VERSION ""

NS_ :

BS_:

BU_:

BO_ 3221225472 VECTOR__INDEPENDENT_SIG_MSG: 0 Vector__XXX
 SG_ StateOfChargeBMS : 0|8@0+ (0.5,3) [0|100] "%" Vector__XXX
 SG_ response : 0|16@0+ (1,0) [0|0] "unit" Vector__XXX
 SG_ service : 0|8@0+ (1,0) [0|0] "" Vector__XXX
 SG_ MinCellVoltage : 0|8@0+ (0.02,0) [2.8|4.2] "V" Vector__XXX
 SG_ MaxCellVoltage : 0|8@0+ (0.02,0) [2.8|4.2] "V" Vector__XXX
 SG_ StateOfChargeDisplay : 0|8@0+ (0.5,3) [0|0] "%" Vector__XXX
 SG_ BatteryTemperature1 : 0|8@0- (1,0) [0|0] "degC" Vector__XXX
 SG_ BatteryTemperature2 : 0|8@0- (1,0) [0|0] "degC" Vector__XXX
 SG_ BatteryTemperature3 : 0|8@0- (1,0) [0|0] "degC" Vector__XXX
 SG_ BatteryTemperature4 : 0|8@0- (1,0) [0|0] "degC" Vector__XXX
 SG_ BatteryMinTemperature : 0|8@0- (1,0) [0|0] "degC" Vector__XXX
 SG_ BatteryMaxTemperature : 0|8@0- (1,0) [0|0] "degC" Vector__XXX
 SG_ BatteryHeaterTemperature1 : 0|8@0- (1,0) [0|0] "degC" Vector__XXX
 SG_ BatteryVoltageAuxillary : 0|8@0+ (0.1,0) [11|14.6] "V" Vector__XXX
 SG_ BatteryTemperature5 : 0|8@0- (1,0) [0|0.5] "V" Vector__XXX
 SG_ BatteryFanFeedback : 0|8@0+ (1,0) [0|120] "Hz" Vector__XXX
 SG_ BatteryFanStatus : 0|8@0+ (1,0) [0|9] "" Vector__XXX
 SG_ NormalChargePort : 0|1@0+ (1,0) [0|0] "" Vector__XXX
 SG_ RapidChargePort : 0|1@0+ (1,0) [0|0] "" Vector__XXX
 SG_ OperatingTime : 0|32@0+ (0.00027777777,0) [0|1000000] "hours" Vector__XXX
 SG_ MinDeterioration : 0|16@0+ (0.1,0) [0|100] "%" Vector__XXX
 SG_ MinDeteriorationCellNo : 0|8@0+ (1,0) [0|98] "" Vector__XXX
 SG_ MinCellVoltageCellNo : 0|8@0+ (1,0) [0|0] "" Vector__XXX
 SG_ MaxCellVoltageCellNo : 0|8@0+ (1,0) [0|0] "" Vector__XXX
 SG_ Charging : 0|1@0+ (1,0) [0|0] "" Vector__XXX
 SG_ CCC_CumulativeChargeCurrent : 0|32@0+ (0.1,0) [0|1000000] "Ah" Vector__XXX
 SG_ CDC_CumulativeDischargeCurrent : 0|32@0+ (0.1,0) [0|1000000] "Ah" Vector__XXX
 SG_ CEC_CumulativeEnergyCharged : 0|32@0+ (0.1,0) [0|1000000] "kWh" Vector__XXX
 SG_ CED_CumulativeEnergyDischarged : 0|32@0+ (0.1,0) [0|1000000] "kWh" Vector__XXX
 SG_ BMSMainRelay : 0|1@0+ (1,0) [0|0] "" Vector__XXX
 SG_ BMSIgnition : 0|1@0+ (1,0) [0|0] "" Vector__XXX
 SG_ BatteryDCVoltage : 0|16@0+ (0.1,0) [0|0] "V" Vector__XXX
 SG_ BatteryCurrent : 0|16@0- (0.1,0) [-230|230] "A" Vector__XXX
 SG_ BatteryAvailableChargePower : 0|16@0+ (0.01,0) [0|270] "kW" Vector__XXX
 SG_ BatteryAvailableDischargePower : 0|16@0+ (0.01,0) [0|270] "kW" Vector__XXX
 SG_ CellVoltage01 : 0|8@0+ (0.02,0) [2.8|4.2] "V" Vector__XXX
 SG_ CellVoltage02 : 0|8@0+ (0.02,0) [2.8|4.2] "V" Vector__XXX
 SG_ CellVoltage03 : 0|8@0+ (0.02,0) [2.8|4.2] "V" Vector__XXX
 SG_ CellVoltage04 : 0|8@0+ (0.02,0) [2.8|4.2] "V" Vector__XXX
 SG_ CellVoltage05 : 0|8@0+ (0.02,0) [2.8|4.2] "V" Vector__XXX
 SG_ CellVoltage06 : 0|8@0+ (0.02,0) [2.8|4.2] "V" Vector__XXX
 SG_ CellVoltage07 : 0|8@0+ (0.02,0) [2.8|4.2] "V" Vector__XXX
 SG_ CellVoltage08 : 0|8@0+ (0.02,0) [2.8|4.2] "V" Vector__XXX
 SG_ CellVoltage09 : 0|8@0+ (0.02,0) [2.8|4.2] "V" Vector__XXX
 SG_ CellVoltage10 : 0|8@0+ (0.02,0) [2.8|4.2] "V" Vector__XXX
 SG_ CellVoltage11 : 0|8@0+ (0.02,0) [2.8|4.2] "V" Vector__XXX
 SG_ CellVoltage12 : 0|8@0+ (0.02,0) [2.8|4.2] "V" Vector__XXX
 SG_ CellVoltage13 : 0|8@0+ (0.02,0) [2.8|4.2] "V" Vector__XXX
 SG_ CellVoltage14 : 0|8@0+ (0.02,0) [2.8|4.2] "V" Vector__XXX
 SG_ CellVoltage15 : 0|8@0+ (0.02,0) [2.8|4.2] "V" Vector__XXX
 SG_ CellVoltage16 : 0|8@0+ (0.02,0) [2.8|4.2] "V" Vector__XXX
 SG_ CellVoltage17 : 0|8@0+ (0.02,0) [2.8|4.2] "V" Vector__XXX
 SG_ CellVoltage18 : 0|8@0+ (0.02,0) [2.8|4.2] "V" Vector__XXX
 SG_ CellVoltage19 : 0|8@0+ (0.02,0) [2.8|4.2] "V" Vector__XXX
 SG_ CellVoltage20 : 0|8@0+ (0.02,0) [2.8|4.2] "V" Vector__XXX
 SG_ StateOfHealth : 0|16@0+ (0.1,0) [0|100] "%" Vector__XXX
 SG_ IndoorTemperature : 0|8@0+ (0.5,-40) [-50|50] "degC" Vector__XXX
 SG_ response : 0|16@0+ (1,0) [0|0] "unit" Vector__XXX
 SG_ service : 0|8@0+ (1,0) [0|0] "" Vector__XXX
 SG_ OutdoorTemperature : 0|8@0+ (0.5,-40) [-50|50] "degC" Vector__XXX
 SG_ VehicleSpeed : 0|8@0+ (1,0) [0|200] "kmh" Vector__XXX
 SG_ response : 0|16@0+ (1,0) [0|0] "" Vector__XXX
 SG_ service : 0|8@0+ (1,0) [0|0] "" Vector__XXX
 SG_ TirePressureFrontLeft : 0|8@0+ (0.2,0) [0|120] "psi" Vector__XXX
 SG_ TirePressureFrontRight : 0|8@0+ (0.2,0) [0|120] "psi" Vector__XXX
 SG_ TirePressureBackLeft : 0|8@0+ (0.2,0) [0|120] "psi" Vector__XXX
 SG_ TirePressureBackRight : 0|8@0+ (0.2,0) [0|120] "psi" Vector__XXX
 SG_ TireTemperatureFrontLeft : 0|8@0+ (1,-50) [-40|65] "degC" Vector__XXX
 SG_ TireTemperatureFrontRight : 0|8@0+ (1,-50) [-40|65] "degC" Vector__XXX
 SG_ TireTemperatureBackLeft : 0|8@0+ (1,-50) [-40|65] "degC" Vector__XXX
 SG_ TireTemperatureBackRight : 0|8@0+ (1,-50) [-40|65] "degC" Vector__XXX

BO_ 3 gnss_pos: 8 Vector__XXX
 SG_ PositionAccuracy : 58|6@1+ (1,0) [0|63] "m" Vector__XXX
 SG_ Latitude : 1|28@1+ (1E-006,-90) [-90|90] "deg" Vector__XXX
 SG_ Longitude : 29|29@1+ (1E-006,-180) [-180|180] "deg" Vector__XXX
 SG_ PositionValid : 0|1@1+ (1,0) [0|1] "" Vector__XXX

BO_ 2 gnss_time: 6 Vector__XXX
 SG_ TimeValid : 0|1@1+ (1,0) [0|1] "" Vector__XXX
 SG_ TimeConfirmed : 1|1@1+ (1,0) [0|1] "" Vector__XXX
 SG_ Epoch : 8|40@1+ (0.001,1577840400) [1577840400|2677352027] "sec" Vector__XXX

BO_ 5 gnss_attitude: 8 Vector__XXX
 SG_ AttitudeValid : 0|1@1+ (1,0) [0|1] "" Vector__XXX
 SG_ Roll : 1|12@1+ (0.1,-180) [-180|180] "deg" Vector__XXX
 SG_ Pitch : 22|12@1+ (0.1,-90) [-90|90] "deg" Vector__XXX
 SG_ Heading : 43|12@1+ (0.1,0) [0|360] "deg" Vector__XXX
 SG_ RollAccuracy : 13|9@1+ (0.1,0) [0|50] "deg" Vector__XXX
 SG_ PitchAccuracy : 34|9@1+ (0.1,0) [0|50] "deg" Vector__XXX
 SG_ HeadingAccuracy : 55|9@1+ (0.1,0) [0|50] "deg" Vector__XXX

BO_ 6 gnss_odo: 8 Vector__XXX
 SG_ DistanceTrip : 1|22@1+ (1,0) [0|4194303] "m" Vector__XXX
 SG_ DistanceAccuracy : 23|19@1+ (1,0) [0|524287] "m" Vector__XXX
 SG_ DistanceValid : 0|1@1+ (1,0) [0|1] "" Vector__XXX
 SG_ DistanceTotal : 42|22@1+ (1,0) [0|4194303] "km" Vector__XXX

BO_ 1 gnss_status: 1 Vector__XXX
 SG_ FixType : 0|3@1+ (1,0) [0|5] "" Vector__XXX
 SG_ Satellites : 3|5@1+ (1,0) [0|31] "" Vector__XXX

BO_ 4 gnss_altitude: 4 Vector__XXX
 SG_ AltitudeValid : 0|1@1+ (1,0) [0|1] "" Vector__XXX
 SG_ Altitude : 1|18@1+ (0.1,-6000) [-6000|20000] "m" Vector__XXX
 SG_ AltitudeAccuracy : 19|13@1+ (1,0) [0|8000] "m" Vector__XXX

BO_ 8 gnss_geofence: 2 Vector__XXX
 SG_ FenceValid : 0|1@1+ (1,0) [0|1] "" Vector__XXX
 SG_ FenceCombined : 1|2@1+ (1,0) [0|1] "" Vector__XXX
 SG_ Fence1 : 8|2@1+ (1,0) [0|1] "" Vector__XXX
 SG_ Fence2 : 10|2@1+ (1,0) [0|1] "" Vector__XXX
 SG_ Fence3 : 12|2@1+ (1,0) [0|1] "" Vector__XXX
 SG_ Fence4 : 14|2@1+ (1,0) [0|1] "" Vector__XXX

BO_ 7 gnss_speed: 5 Vector__XXX
 SG_ Speed : 1|20@1+ (0.001,0) [0|1048.575] "m/s" Vector__XXX
 SG_ SpeedAccuracy : 21|19@1+ (0.001,0) [0|524.287] "m/s" Vector__XXX
 SG_ SpeedValid : 0|1@1+ (1,0) [0|1] "" Vector__XXX

BO_ 9 gnss_imu: 8 Vector__XXX
 SG_ AccelerationX : 1|10@1+ (0.125,-64) [-64|63.875] "m/s^2" Vector__XXX
 SG_ AccelerationY : 11|10@1+ (0.125,-64) [-64|63.875] "m/s^2" Vector__XXX
 SG_ AccelerationZ : 21|10@1+ (0.125,-64) [-64|63.875] "m/s^2" Vector__XXX
 SG_ AngularRateX : 31|11@1+ (0.25,-256) [-256|255.75] "deg/s" Vector__XXX
 SG_ AngularRateY : 42|11@1+ (0.25,-256) [-256|255.75] "deg/s" Vector__XXX
 SG_ AngularRateZ : 53|11@1+ (0.25,-256) [-256|255.75] "deg/s" Vector__XXX
 SG_ ImuValid : 0|1@1+ (1,0) [0|1] "" Vector__XXX

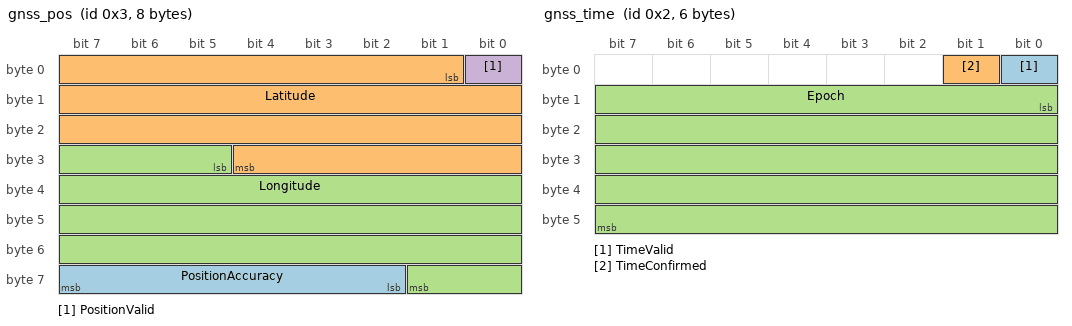
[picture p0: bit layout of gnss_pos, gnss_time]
BO_ 19 gnss_pos: 8 Vector__XXX
 SG_ PositionAccuracy : 58|6@1+ (1,0) [0|63] "m" Vector__XXX
 SG_ Latitude : 1|28@1+ (1E-006,-90) [-90|90] "deg" Vector__XXX
 SG_ Longitude : 29|29@1+ (1E-006,-180) [-180|180] "deg" Vector__XXX
 SG_ PositionValid : 0|1@1+ (1,0) [0|1] "" Vector__XXX

BO_ 18 gnss_time: 6 Vector__XXX
 SG_ TimeValid : 0|1@1+ (1,0) [0|1] "" Vector__XXX
 SG_ TimeConfirmed : 1|1@1+ (1,0) [0|1] "" Vector__XXX
 SG_ Epoch : 8|40@1+ (0.001,1577840400) [1577840400|2677352027] "sec" Vector__XXX

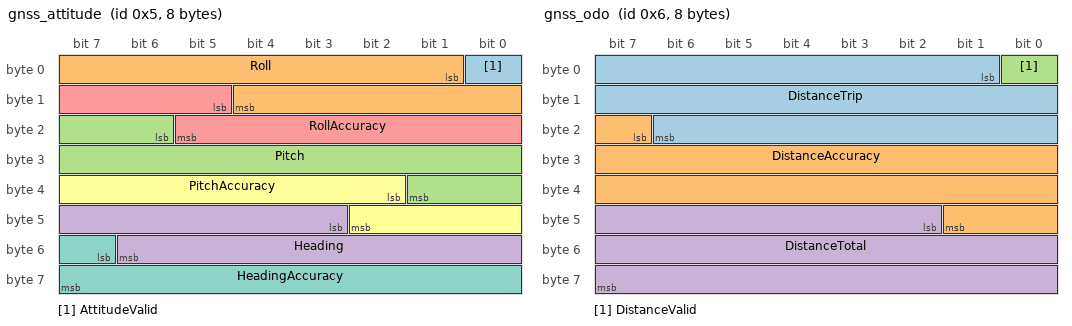
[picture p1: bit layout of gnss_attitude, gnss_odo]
BO_ 21 gnss_attitude: 8 Vector__XXX
 SG_ AttitudeValid : 0|1@1+ (1,0) [0|1] "" Vector__XXX
 SG_ Roll : 1|12@1+ (0.1,-180) [-180|180] "deg" Vector__XXX
 SG_ Pitch : 22|12@1+ (0.1,-90) [-90|90] "deg" Vector__XXX
 SG_ Heading : 43|12@1+ (0.1,0) [0|360] "deg" Vector__XXX
 SG_ RollAccuracy : 13|9@1+ (0.1,0) [0|50] "deg" Vector__XXX
 SG_ PitchAccuracy : 34|9@1+ (0.1,0) [0|50] "deg" Vector__XXX
 SG_ HeadingAccuracy : 55|9@1+ (0.1,0) [0|50] "deg" Vector__XXX

BO_ 22 gnss_odo: 8 Vector__XXX
 SG_ DistanceTrip : 1|22@1+ (1,0) [0|4194303] "m" Vector__XXX
 SG_ DistanceAccuracy : 23|19@1+ (1,0) [0|524287] "m" Vector__XXX
 SG_ DistanceValid : 0|1@1+ (1,0) [0|1] "" Vector__XXX
 SG_ DistanceTotal : 42|22@1+ (1,0) [0|4194303] "km" Vector__XXX

BO_ 17 gnss_status: 1 Vector__XXX
 SG_ FixType : 0|3@1+ (1,0) [0|5] "" Vector__XXX
 SG_ Satellites : 3|5@1+ (1,0) [0|31] "" Vector__XXX

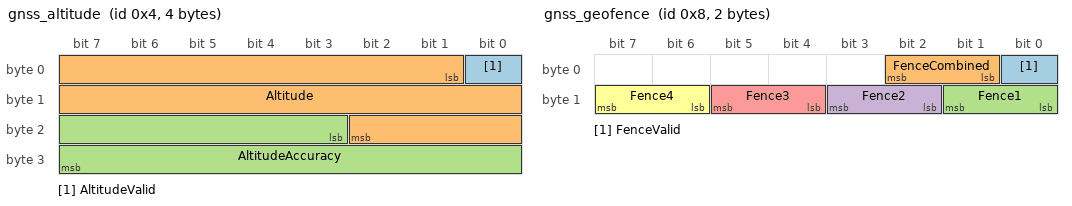
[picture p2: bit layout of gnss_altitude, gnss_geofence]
BO_ 20 gnss_altitude: 4 Vector__XXX
 SG_ AltitudeValid : 0|1@1+ (1,0) [0|1] "" Vector__XXX
 SG_ Altitude : 1|18@1+ (0.1,-6000) [-6000|20000] "m" Vector__XXX
 SG_ AltitudeAccuracy : 19|13@1+ (1,0) [0|8000] "m" Vector__XXX

BO_ 24 gnss_geofence: 2 Vector__XXX
 SG_ FenceValid : 0|1@1+ (1,0) [0|1] "" Vector__XXX
 SG_ FenceCombined : 1|2@1+ (1,0) [0|1] "" Vector__XXX
 SG_ Fence1 : 8|2@1+ (1,0) [0|1] "" Vector__XXX
 SG_ Fence2 : 10|2@1+ (1,0) [0|1] "" Vector__XXX
 SG_ Fence3 : 12|2@1+ (1,0) [0|1] "" Vector__XXX
 SG_ Fence4 : 14|2@1+ (1,0) [0|1] "" Vector__XXX

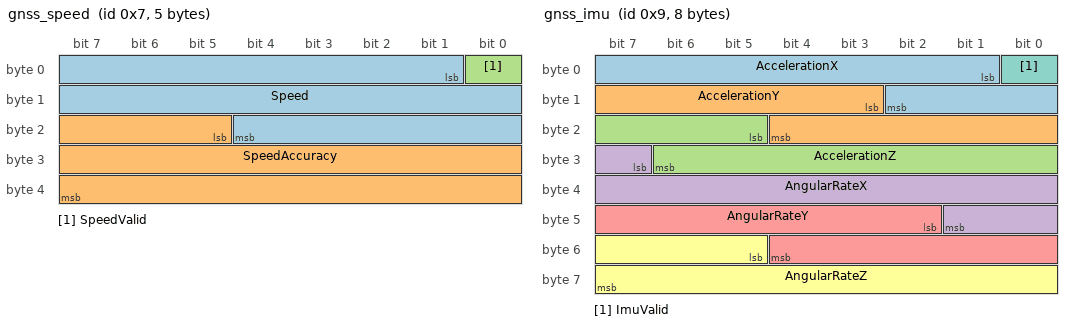
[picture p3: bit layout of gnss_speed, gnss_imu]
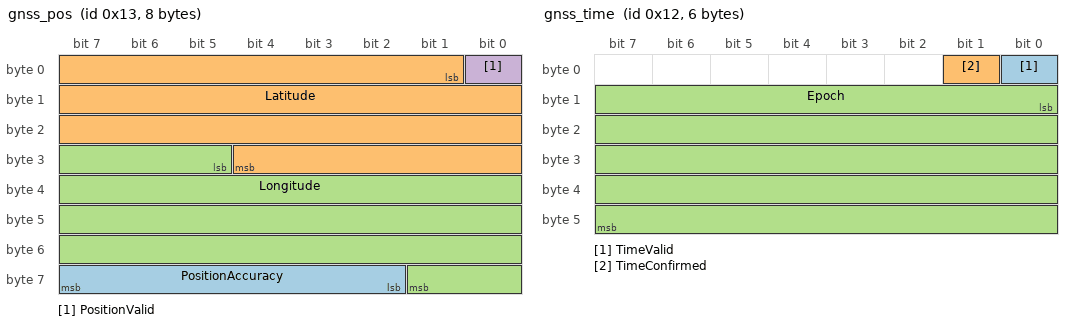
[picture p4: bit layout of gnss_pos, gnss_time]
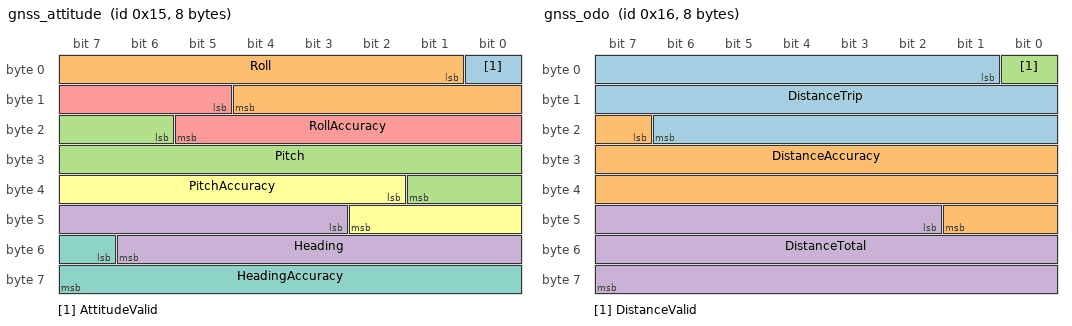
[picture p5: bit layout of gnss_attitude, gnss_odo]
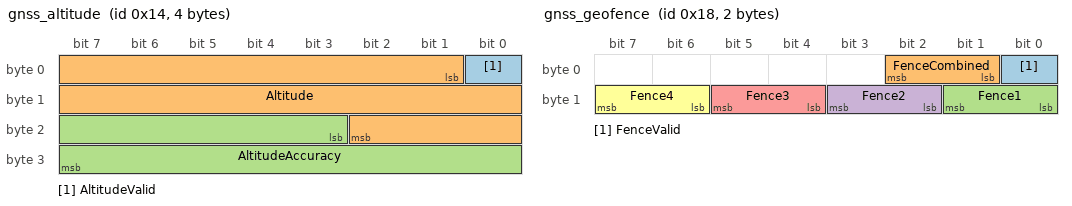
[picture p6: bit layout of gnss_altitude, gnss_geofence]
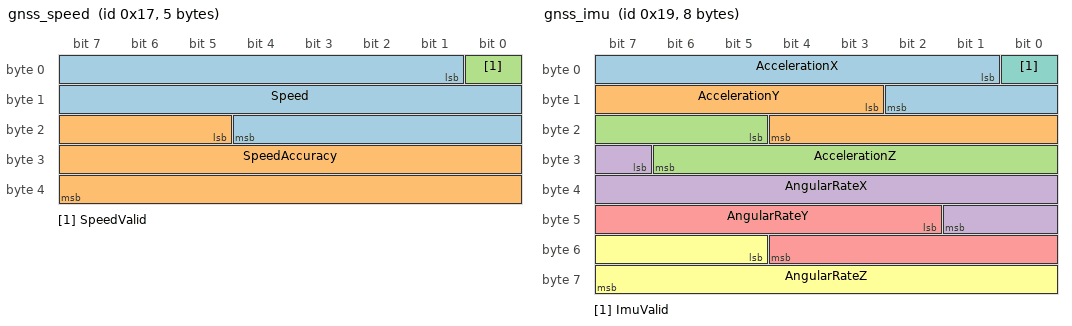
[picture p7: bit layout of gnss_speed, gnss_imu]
BO_ 23 gnss_speed: 5 Vector__XXX
 SG_ Speed : 1|20@1+ (0.001,0) [0|1048.575] "m/s" Vector__XXX
 SG_ SpeedAccuracy : 21|19@1+ (0.001,0) [0|524.287] "m/s" Vector__XXX
 SG_ SpeedValid : 0|1@1+ (1,0) [0|1] "" Vector__XXX

BO_ 25 gnss_imu: 8 Vector__XXX
 SG_ AccelerationX : 1|10@1+ (0.125,-64) [-64|63.875] "m/s^2" Vector__XXX
 SG_ AccelerationY : 11|10@1+ (0.125,-64) [-64|63.875] "m/s^2" Vector__XXX
 SG_ AccelerationZ : 21|10@1+ (0.125,-64) [-64|63.875] "m/s^2" Vector__XXX
 SG_ AngularRateX : 31|11@1+ (0.25,-256) [-256|255.75] "deg/s" Vector__XXX
 SG_ AngularRateY : 42|11@1+ (0.25,-256) [-256|255.75] "deg/s" Vector__XXX
 SG_ AngularRateZ : 53|11@1+ (0.25,-256) [-256|255.75] "deg/s" Vector__XXX
 SG_ ImuValid : 0|1@1+ (1,0) [0|1] "" Vector__XXX

CM_ BO_ 3221225472 "This is a message for not used signals, created by Vector CANdb++ DBC OLE DB Provider.";
CM_ BO_ 3 "GNSS position";
CM_ SG_ 3 PositionAccuracy "Accuracy of position";
CM_ SG_ 3 Latitude "Latitude";
CM_ SG_ 3 Longitude "Longitude";
CM_ SG_ 3 PositionValid "Position validity";
CM_ BO_ 2 "GNSS time";
CM_ SG_ 2 TimeValid "Time validity";
CM_ SG_ 2 TimeConfirmed "Time confirmed";
CM_ SG_ 2 Epoch "Epoch time";
CM_ BO_ 5 "GNSS attitude";
CM_ SG_ 5 AttitudeValid "Attitude validity";
CM_ SG_ 5 Roll "Vehicle roll";
CM_ SG_ 5 Pitch "Vehicle pitch";
CM_ SG_ 5 Heading "Vehicle heading";
CM_ SG_ 5 RollAccuracy "Vehicle roll accuracy";
CM_ SG_ 5 PitchAccuracy "Vehicle pitch accuracy";
CM_ SG_ 5 HeadingAccuracy "Vehicle heading accuracy";
CM_ BO_ 6 "GNSS odometer";
CM_ SG_ 6 DistanceTrip "Distance traveled since last reset";
CM_ SG_ 6 DistanceAccuracy "Distance accuracy (1-sigma)";
CM_ SG_ 6 DistanceTotal "Distance traveled in total";
CM_ BO_ 1 "GNSS information";
CM_ SG_ 1 FixType "Fix type";
CM_ SG_ 1 Satellites "Number of satellites used";
CM_ BO_ 4 "GNSS altitude";
CM_ SG_ 4 AltitudeValid "Altitude validity";
CM_ SG_ 4 Altitude "Altitude";
CM_ SG_ 4 AltitudeAccuracy "Accuracy of altitude";
CM_ BO_ 8 "GNSS geofence(s)";
CM_ SG_ 8 FenceValid "Geofencing status";
CM_ SG_ 8 FenceCombined "Combined (logical OR) state of all geofences";
CM_ SG_ 8 Fence1 "Geofence 1 state";
CM_ SG_ 8 Fence2 "Geofence 2 state";
CM_ SG_ 8 Fence3 "Geofence 3 state";
CM_ SG_ 8 Fence4 "Geofence 4 state";
CM_ BO_ 7 "GNSS speed";
CM_ SG_ 7 Speed "Speed";
CM_ SG_ 7 SpeedAccuracy "Speed accuracy";
CM_ BO_ 9 "GNSS IMU";
CM_ SG_ 9 AccelerationX "X acceleration with a resolution of 0.125 m/s^2";
CM_ SG_ 9 AccelerationY "Y acceleration with a resolution of 0.125 m/s^2";
CM_ SG_ 9 AccelerationZ "Z acceleration with a resolution of 0.125 m/s^2";
CM_ SG_ 9 AngularRateX "X angular rate with a resolution of 0.25 deg/s";
CM_ SG_ 9 AngularRateY "Y angular rate with a resolution of 0.25 deg/s";
CM_ SG_ 9 AngularRateZ "Z angular rate with a resolution of 0.25 deg/s";
CM_ BO_ 19 "GNSS position";
CM_ SG_ 19 PositionAccuracy "Accuracy of position";
CM_ SG_ 19 Latitude "Latitude";
CM_ SG_ 19 Longitude "Longitude";
CM_ SG_ 19 PositionValid "Position validity";
CM_ BO_ 18 "GNSS time";
CM_ SG_ 18 TimeValid "Time validity";
CM_ SG_ 18 TimeConfirmed "Time confirmed";
CM_ SG_ 18 Epoch "Epoch time";
CM_ BO_ 21 "GNSS attitude";
CM_ SG_ 21 AttitudeValid "Attitude validity";
CM_ SG_ 21 Roll "Vehicle roll";
CM_ SG_ 21 Pitch "Vehicle pitch";
CM_ SG_ 21 Heading "Vehicle heading";
CM_ SG_ 21 RollAccuracy "Vehicle roll accuracy";
CM_ SG_ 21 PitchAccuracy "Vehicle pitch accuracy";
CM_ SG_ 21 HeadingAccuracy "Vehicle heading accuracy";
CM_ BO_ 22 "GNSS odometer";
CM_ SG_ 22 DistanceTrip "Distance traveled since last reset";
CM_ SG_ 22 DistanceAccuracy "Distance accuracy (1-sigma)";
CM_ SG_ 22 DistanceTotal "Distance traveled in total";
CM_ BO_ 17 "GNSS information";
CM_ SG_ 17 FixType "Fix type";
CM_ SG_ 17 Satellites "Number of satellites used";
CM_ BO_ 20 "GNSS altitude";
CM_ SG_ 20 AltitudeValid "Altitude validity";
CM_ SG_ 20 Altitude "Altitude";
CM_ SG_ 20 AltitudeAccuracy "Accuracy of altitude";
CM_ BO_ 24 "GNSS geofence(s)";
CM_ SG_ 24 FenceValid "Geofencing status";
CM_ SG_ 24 FenceCombined "Combined (logical OR) state of all geofences";
CM_ SG_ 24 Fence1 "Geofence 1 state";
CM_ SG_ 24 Fence2 "Geofence 2 state";
CM_ SG_ 24 Fence3 "Geofence 3 state";
CM_ SG_ 24 Fence4 "Geofence 4 state";
CM_ BO_ 23 "GNSS speed";
CM_ SG_ 23 Speed "Speed";
CM_ SG_ 23 SpeedAccuracy "Speed accuracy";
CM_ BO_ 25 "GNSS IMU";
CM_ SG_ 25 AccelerationX "X acceleration with a resolution of 0.125 m/s^2";
CM_ SG_ 25 AccelerationY "Y acceleration with a resolution of 0.125 m/s^2";
CM_ SG_ 25 AccelerationZ "Z acceleration with a resolution of 0.125 m/s^2";
CM_ SG_ 25 AngularRateX "X angular rate with a resolution of 0.25 deg/s";
CM_ SG_ 25 AngularRateY "Y angular rate with a resolution of 0.25 deg/s";
CM_ SG_ 25 AngularRateZ "Z angular rate with a resolution of 0.25 deg/s";
BA_DEF_  "ProtocolType" STRING ;
BA_DEF_DEF_  "ProtocolType" "";
VAL_ 3 PositionValid 0 "Invalid" 1 "Valid" ;
VAL_ 2 TimeValid 0 "Invalid" 1 "Valid" ;
VAL_ 2 TimeConfirmed 0 "Unconfirmed" 1 "Confirmed" ;
VAL_ 5 AttitudeValid 0 "Invalid" 1 "Valid" ;
VAL_ 6 DistanceValid 0 "Invalid" 1 "Valid" ;
VAL_ 1 FixType 0 "No fix" 1 "Dead reckoning only" 2 "2D-fix" 3 "3D-fix" 4 "GNSS + dead reckoning combined" 5 "Time only fix" ;
VAL_ 4 AltitudeValid 0 "Invalid" 1 "Valid" ;
VAL_ 8 FenceValid 0 "Invalid" 1 "Valid" ;
VAL_ 8 FenceCombined 0 "Unknown" 1 "Inside" 2 "Outside" ;
VAL_ 8 Fence1 0 "Unknown" 1 "Inside" 2 "Outside" ;
VAL_ 8 Fence2 0 "Unknown" 1 "Inside" 2 "Outside" ;
VAL_ 8 Fence3 0 "Unknown" 1 "Inside" 2 "Outside" ;
VAL_ 8 Fence4 0 "Unknown" 1 "Inside" 2 "Outside" ;
VAL_ 7 SpeedValid 0 "Invalid" 1 "Valid" ;
VAL_ 9 ImuValid 0 "Invalid" 1 "Valid" ;
VAL_ 19 PositionValid 0 "Invalid" 1 "Valid" ;
VAL_ 18 TimeValid 0 "Invalid" 1 "Valid" ;
VAL_ 18 TimeConfirmed 0 "Unconfirmed" 1 "Confirmed" ;
VAL_ 21 AttitudeValid 0 "Invalid" 1 "Valid" ;
VAL_ 22 DistanceValid 0 "Invalid" 1 "Valid" ;
VAL_ 17 FixType 0 "No fix" 1 "Dead reckoning only" 2 "2D-fix" 3 "3D-fix" 4 "GNSS + dead reckoning combined" 5 "Time only fix" ;
VAL_ 20 AltitudeValid 0 "Invalid" 1 "Valid" ;
VAL_ 24 FenceValid 0 "Invalid" 1 "Valid" ;
VAL_ 24 FenceCombined 0 "Unknown" 1 "Inside" 2 "Outside" ;
VAL_ 24 Fence1 0 "Unknown" 1 "Inside" 2 "Outside" ;
VAL_ 24 Fence2 0 "Unknown" 1 "Inside" 2 "Outside" ;
VAL_ 24 Fence3 0 "Unknown" 1 "Inside" 2 "Outside" ;
VAL_ 24 Fence4 0 "Unknown" 1 "Inside" 2 "Outside" ;
VAL_ 23 SpeedValid 0 "Invalid" 1 "Valid" ;
VAL_ 25 ImuValid 0 "Invalid" 1 "Valid" ;
